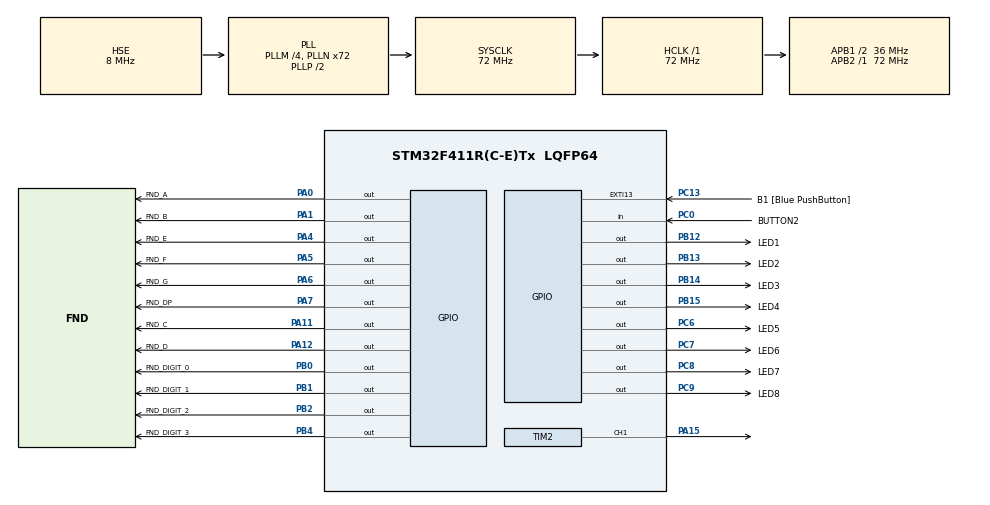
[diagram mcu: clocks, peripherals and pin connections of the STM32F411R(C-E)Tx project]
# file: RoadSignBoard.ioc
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Mcu.Family=STM32F4
Mcu.Name=STM32F411R(C-E)Tx
Mcu.Package=LQFP64
NVIC.PriorityGroup=NVIC_PRIORITYGROUP_0
NVIC.TIM2_IRQn=true\:0\:0\:false\:false\:true\:true\:true
PA0-WKUP.GPIO_Label=FND_A
PA0-WKUP.Signal=GPIO_Output
PA1.GPIO_Label=FND_B
PA1.Signal=GPIO_Output
PA11.GPIO_Label=FND_C
PA11.Signal=GPIO_Output
PA12.GPIO_Label=FND_D
PA12.Signal=GPIO_Output
PA13.GPIO_Label=TMS
PA13.Mode=Serial_Wire
PA13.Signal=SYS_JTMS-SWDIO
PA14.GPIO_Label=TCK
PA14.Mode=Serial_Wire
PA14.Signal=SYS_JTCK-SWCLK
PA15.Signal=S_TIM2_CH1_ETR
PA4.GPIO_Label=FND_E
PA4.Signal=GPIO_Output
PA5.GPIO_Label=FND_F
PA5.Signal=GPIO_Output
PA6.GPIO_Label=FND_G
PA6.Signal=GPIO_Output
PA7.GPIO_Label=FND_DP
PA7.Signal=GPIO_Output
PB0.GPIO_Label=FND_DIGIT_0
PB0.Signal=GPIO_Output
PB1.GPIO_Label=FND_DIGIT_1
PB1.Signal=GPIO_Output
PB12.GPIO_Label=LED1
PB12.Signal=GPIO_Output
PB13.GPIO_Label=LED2
PB13.Signal=GPIO_Output
PB14.GPIO_Label=LED3
PB14.Signal=GPIO_Output
PB15.GPIO_Label=LED4
PB15.Signal=GPIO_Output
PB2.GPIO_Label=FND_DIGIT_2
PB2.Signal=GPIO_Output
PB3.GPIO_Label=SWO
PB3.Signal=SYS_JTDO-SWO
PB4.GPIO_Label=FND_DIGIT_3
PB4.Signal=GPIO_Output
PC0.GPIO_Label=BUTTON2
PC0.Signal=GPIO_Input
PC13-ANTI_TAMP.GPIO_Label=B1 [Blue PushButton]
PC13-ANTI_TAMP.GPIO_ModeDefaultEXTI=GPIO_MODE_IT_FALLING
PC13-ANTI_TAMP.Signal=GPXTI13
PC14-OSC32_IN.Mode=LSE-External-Oscillator
PC14-OSC32_IN.Signal=RCC_OSC32_IN
PC15-OSC32_OUT.Mode=LSE-External-Oscillator
PC15-OSC32_OUT.Signal=RCC_OSC32_OUT
PC6.GPIO_Label=LED5
PC6.Signal=GPIO_Output
PC7.GPIO_Label=LED6
PC7.Signal=GPIO_Output
PC8.GPIO_Label=LED7
PC8.Signal=GPIO_Output
PC9.GPIO_Label=LED8
PC9.Signal=GPIO_Output
PH0\ -\ OSC_IN.Mode=HSE-External-Clock-Source
PH0\ -\ OSC_IN.Signal=RCC_OSC_IN
PH1\ -\ OSC_OUT.Mode=HSE-External-Clock-Source
PH1\ -\ OSC_OUT.Signal=RCC_OSC_OUT
ProjectManager.HeapSize=0x200
ProjectManager.StackSize=0x400
ProjectManager.TargetToolchain=STM32CubeIDE
RCC.48MHZClocksFreq_Value=36000000
RCC.AHBFreq_Value=72000000
RCC.APB1CLKDivider=RCC_HCLK_DIV2
RCC.APB1Freq_Value=36000000
RCC.APB1TimFreq_Value=72000000
RCC.APB2Freq_Value=72000000
RCC.APB2TimFreq_Value=72000000
RCC.CortexFreq_Value=72000000
RCC.FLatency-AdvancedSettings=FLASH_LATENCY_2
RCC.HCLKFreq_Value=72000000
RCC.HSE_VALUE=8000000
RCC.HSI_VALUE=16000000
RCC.PLLM=4
RCC.PLLN=72
RCC.PLLSourceVirtual=RCC_PLLSOURCE_HSE
RCC.SYSCLKFreq_VALUE=72000000
RCC.SYSCLKSource=RCC_SYSCLKSOURCE_PLLCLK
RCC.VCOOutputFreq_Value=144000000
SH.S_TIM2_CH1_ETR.0=TIM2_CH1,PWM Generation1 CH1
TIM2.Channel-PWM\ Generation1\ CH1=TIM_CHANNEL_1
TIM2.OCFastMode_PWM-PWM\ Generation1\ CH1=TIM_OCFAST_ENABLE
TIM2.Period=65535
TIM2.Prescaler=720-1
VP_TIM2_VS_ClockSourceINT.Mode=Internal
board=NUCLEO-F411RE

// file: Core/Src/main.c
/* USER CODE BEGIN Header */
/**
  ******************************************************************************
  * @file           : main.c
  * @brief          : Main program body
  ******************************************************************************
  * @attention
  *
  * <h2><center>&copy; Copyright (c) 2025 STMicroelectronics.
  * All rights reserved.</center></h2>
  *
  * This software component is licensed by ST under BSD 3-Clause license,
  * the "License"; You may not use this file except in compliance with the
  * License. You may obtain a copy of the License at:
  *                        opensource.org/licenses/BSD-3-Clause
  *
  ******************************************************************************
  */
/* USER CODE END Header */
#include "main.h"

/* USER CODE BEGIN Includes */
#include "../Controller/RoadSignBoardController.h"
/* USER CODE END Includes */

TIM_HandleTypeDef htim2;

void SystemClock_Config(void);
static void MX_GPIO_Init(void);
static void MX_TIM2_Init(void);

/* USER CODE BEGIN 0 */
void HAL_TIM_PeriodElapsedCallback(TIM_HandleTypeDef *htim){
	if(htim->Instance == TIM2){
		FND_ISR_Process();
	}
}
/* USER CODE END 0 */

int main(void)
{

  /* MCU Configuration--------------------------------------------------------*/

  /* Reset of all peripherals, Initializes the Flash interface and the Systick. */
  HAL_Init();

  /* Configure the system clock */
  SystemClock_Config();

  /* Initialize all configured peripherals */
  MX_GPIO_Init();
  MX_TIM2_Init();
  /* USER CODE BEGIN 2 */
  RoadSignBoard_Init();
  HAL_TIM_Base_Start_IT(&htim2);
  /* USER CODE END 2 */

  /* Infinite loop */
  /* USER CODE BEGIN WHILE */
  while (1)
  {
	  RoadSignBoardController();
    /* USER CODE END WHILE */

  }
}

void SystemClock_Config(void)
{
  RCC_OscInitTypeDef RCC_OscInitStruct = {0};
  RCC_ClkInitTypeDef RCC_ClkInitStruct = {0};

  /** Configure the main internal regulator output voltage
  */
  __HAL_RCC_PWR_CLK_ENABLE();
  __HAL_PWR_VOLTAGESCALING_CONFIG(PWR_REGULATOR_VOLTAGE_SCALE1);
  /** Initializes the RCC Oscillators according to the specified parameters
  * in the RCC_OscInitTypeDef structure.
  */
  RCC_OscInitStruct.OscillatorType = RCC_OSCILLATORTYPE_HSE;
  RCC_OscInitStruct.HSEState = RCC_HSE_BYPASS;
  RCC_OscInitStruct.PLL.PLLState = RCC_PLL_ON;
  RCC_OscInitStruct.PLL.PLLSource = RCC_PLLSOURCE_HSE;
  RCC_OscInitStruct.PLL.PLLM = 4;
  RCC_OscInitStruct.PLL.PLLN = 72;
  RCC_OscInitStruct.PLL.PLLP = RCC_PLLP_DIV2;
  RCC_OscInitStruct.PLL.PLLQ = 4;
  if (HAL_RCC_OscConfig(&RCC_OscInitStruct) != HAL_OK)
  {
    Error_Handler();
  }
  /** Initializes the CPU, AHB and APB buses clocks
  */
  RCC_ClkInitStruct.ClockType = RCC_CLOCKTYPE_HCLK|RCC_CLOCKTYPE_SYSCLK
                              |RCC_CLOCKTYPE_PCLK1|RCC_CLOCKTYPE_PCLK2;
  RCC_ClkInitStruct.SYSCLKSource = RCC_SYSCLKSOURCE_PLLCLK;
  RCC_ClkInitStruct.AHBCLKDivider = RCC_SYSCLK_DIV1;
  RCC_ClkInitStruct.APB1CLKDivider = RCC_HCLK_DIV2;
  RCC_ClkInitStruct.APB2CLKDivider = RCC_HCLK_DIV1;

  if (HAL_RCC_ClockConfig(&RCC_ClkInitStruct, FLASH_LATENCY_2) != HAL_OK)
  {
    Error_Handler();
  }
}

static void MX_TIM2_Init(void)
{

  TIM_ClockConfigTypeDef sClockSourceConfig = {0};
  TIM_MasterConfigTypeDef sMasterConfig = {0};
  TIM_OC_InitTypeDef sConfigOC = {0};

  htim2.Instance = TIM2;
  htim2.Init.Prescaler = 720-1;
  htim2.Init.CounterMode = TIM_COUNTERMODE_UP;
  htim2.Init.Period = 65535;
  htim2.Init.ClockDivision = TIM_CLOCKDIVISION_DIV1;
  htim2.Init.AutoReloadPreload = TIM_AUTORELOAD_PRELOAD_DISABLE;
  if (HAL_TIM_Base_Init(&htim2) != HAL_OK)
  {
    Error_Handler();
  }
  sClockSourceConfig.ClockSource = TIM_CLOCKSOURCE_INTERNAL;
  if (HAL_TIM_ConfigClockSource(&htim2, &sClockSourceConfig) != HAL_OK)
  {
    Error_Handler();
  }
  if (HAL_TIM_PWM_Init(&htim2) != HAL_OK)
  {
    Error_Handler();
  }
  sMasterConfig.MasterOutputTrigger = TIM_TRGO_RESET;
  sMasterConfig.MasterSlaveMode = TIM_MASTERSLAVEMODE_DISABLE;
  if (HAL_TIMEx_MasterConfigSynchronization(&htim2, &sMasterConfig) != HAL_OK)
  {
    Error_Handler();
  }
  sConfigOC.OCMode = TIM_OCMODE_PWM1;
  sConfigOC.Pulse = 0;
  sConfigOC.OCPolarity = TIM_OCPOLARITY_HIGH;
  sConfigOC.OCFastMode = TIM_OCFAST_ENABLE;
  if (HAL_TIM_PWM_ConfigChannel(&htim2, &sConfigOC, TIM_CHANNEL_1) != HAL_OK)
  {
    Error_Handler();
  }
  HAL_TIM_MspPostInit(&htim2);

}

static void MX_GPIO_Init(void)
{
  GPIO_InitTypeDef GPIO_InitStruct = {0};

  /* GPIO Ports Clock Enable */
  __HAL_RCC_GPIOC_CLK_ENABLE();
  __HAL_RCC_GPIOH_CLK_ENABLE();
  __HAL_RCC_GPIOA_CLK_ENABLE();
  __HAL_RCC_GPIOB_CLK_ENABLE();

  /*Configure GPIO pin Output Level */
  HAL_GPIO_WritePin(GPIOA, FND_A_Pin|FND_B_Pin|FND_E_Pin|FND_F_Pin
                          |FND_G_Pin|FND_DP_Pin|FND_C_Pin|FND_D_Pin, GPIO_PIN_RESET);

  /*Configure GPIO pin Output Level */
  HAL_GPIO_WritePin(GPIOB, FND_DIGIT_0_Pin|FND_DIGIT_1_Pin|FND_DIGIT_2_Pin|LED1_Pin
                          |LED2_Pin|LED3_Pin|LED4_Pin|FND_DIGIT_3_Pin, GPIO_PIN_RESET);

  /*Configure GPIO pin Output Level */
  HAL_GPIO_WritePin(GPIOC, LED5_Pin|LED6_Pin|LED7_Pin|LED8_Pin, GPIO_PIN_RESET);

  /*Configure GPIO pin : B1_Pin */
  GPIO_InitStruct.Pin = B1_Pin;
  GPIO_InitStruct.Mode = GPIO_MODE_IT_FALLING;
  GPIO_InitStruct.Pull = GPIO_NOPULL;
  HAL_GPIO_Init(B1_GPIO_Port, &GPIO_InitStruct);

  /*Configure GPIO pin : BUTTON2_Pin */
  GPIO_InitStruct.Pin = BUTTON2_Pin;
  GPIO_InitStruct.Mode = GPIO_MODE_INPUT;
  GPIO_InitStruct.Pull = GPIO_NOPULL;
  HAL_GPIO_Init(BUTTON2_GPIO_Port, &GPIO_InitStruct);

  /*Configure GPIO pins : FND_A_Pin FND_B_Pin FND_E_Pin FND_F_Pin
                           FND_G_Pin FND_DP_Pin FND_C_Pin FND_D_Pin */
  GPIO_InitStruct.Pin = FND_A_Pin|FND_B_Pin|FND_E_Pin|FND_F_Pin
                          |FND_G_Pin|FND_DP_Pin|FND_C_Pin|FND_D_Pin;
  GPIO_InitStruct.Mode = GPIO_MODE_OUTPUT_PP;
  GPIO_InitStruct.Pull = GPIO_NOPULL;
  GPIO_InitStruct.Speed = GPIO_SPEED_FREQ_LOW;
  HAL_GPIO_Init(GPIOA, &GPIO_InitStruct);

  /*Configure GPIO pins : FND_DIGIT_0_Pin FND_DIGIT_1_Pin FND_DIGIT_2_Pin LED1_Pin
                           LED2_Pin LED3_Pin LED4_Pin FND_DIGIT_3_Pin */
  GPIO_InitStruct.Pin = FND_DIGIT_0_Pin|FND_DIGIT_1_Pin|FND_DIGIT_2_Pin|LED1_Pin
                          |LED2_Pin|LED3_Pin|LED4_Pin|FND_DIGIT_3_Pin;
  GPIO_InitStruct.Mode = GPIO_MODE_OUTPUT_PP;
  GPIO_InitStruct.Pull = GPIO_NOPULL;
  GPIO_InitStruct.Speed = GPIO_SPEED_FREQ_LOW;
  HAL_GPIO_Init(GPIOB, &GPIO_InitStruct);

  /*Configure GPIO pins : LED5_Pin LED6_Pin LED7_Pin LED8_Pin */
  GPIO_InitStruct.Pin = LED5_Pin|LED6_Pin|LED7_Pin|LED8_Pin;
  GPIO_InitStruct.Mode = GPIO_MODE_OUTPUT_PP;
  GPIO_InitStruct.Pull = GPIO_NOPULL;
  GPIO_InitStruct.Speed = GPIO_SPEED_FREQ_LOW;
  HAL_GPIO_Init(GPIOC, &GPIO_InitStruct);

}

void Error_Handler(void)
{
  __disable_irq();
  while (1)
  {
  }
}

/************************ (C) COPYRIGHT STMicroelectronics *****END OF FILE****/
